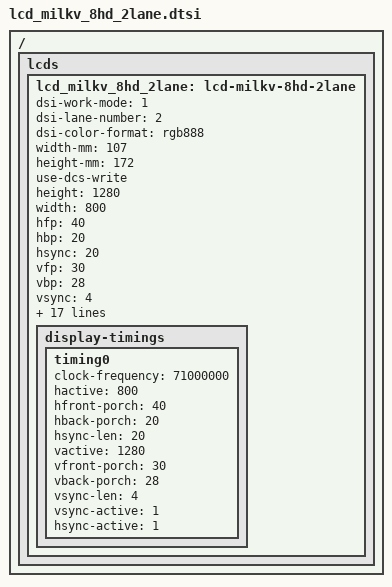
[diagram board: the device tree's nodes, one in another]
// SPDX-License-Identifier: GPL-2.0

/ { lcds: lcds {
	lcd_milkv_8hd_2lane: lcd-milkv-8hd-2lane {
		dsi-work-mode = <1>; /* video burst mode*/
		dsi-lane-number = <2>;
		dsi-color-format = "rgb888";
		width-mm = <107>;
		height-mm = <172>;
		use-dcs-write;

		/*mipi info*/
		height = <1280>;
		width = <800>;
		hfp = <40>;
		hbp = <20>;
		hsync = <20>;
		vfp = <30>;
		vbp = <28>;
		vsync = <4>;
		fps = <60>;
		work-mode = <0>;
		rgb-mode = <3>;
		lane-number = <2>;
		phy-bit-clock = <860000000>;	/* 880 x 1342 * 60 * 24 / 2 = 850,291,200 */
		split-enable = <0>;
		eotp-enable = <0>;
		burst-mode = <2>;
		esd-check-enable = <0>;

		/* DSI_CMD, DSI_MODE, timeout, len, cmd */
		initial-command = [
			39 01 00 02 E0 00
			39 01 00 02 E1 93
			39 01 00 02 E2 65
			39 01 00 02 E3 F8
			39 01 00 02 80 03
			39 01 00 02 E0 01
			39 01 00 02 00 00
			39 01 00 02 01 72
			39 01 00 02 03 00
			39 01 00 02 04 65
			39 01 00 02 0C 74
			39 01 00 02 17 00
			39 01 00 02 18 B7
			39 01 00 02 19 00
			39 01 00 02 1A 00
			39 01 00 02 1B B7
			39 01 00 02 1C 00
			39 01 00 02 24 FE
			39 01 00 02 37 19
			39 01 00 02 38 05
			39 01 00 02 39 00
			39 01 00 02 3A 01
			39 01 00 02 3B 01
			39 01 00 02 3C 70
			39 01 00 02 3D FF
			39 01 00 02 3E FF
			39 01 00 02 3F FF
			39 01 00 02 40 06
			39 01 00 02 41 A0
			39 01 00 02 43 1E
			39 01 00 02 44 0F
			39 01 00 02 45 28
			39 01 00 02 4B 04
			39 01 00 02 55 02
			39 01 00 02 56 01
			39 01 00 02 57 A9
			39 01 00 02 58 0A
			39 01 00 02 59 0A
			39 01 00 02 5A 37
			39 01 00 02 5B 19
			39 01 00 02 5D 78
			39 01 00 02 5E 63
			39 01 00 02 5F 54
			39 01 00 02 60 48
			39 01 00 02 61 45
			39 01 00 02 62 38
			39 01 00 02 63 3D
			39 01 00 02 64 28
			39 01 00 02 65 43
			39 01 00 02 66 41
			39 01 00 02 67 43
			39 01 00 02 68 62
			39 01 00 02 69 50
			39 01 00 02 6A 57
			39 01 00 02 6B 49
			39 01 00 02 6C 44
			39 01 00 02 6D 37
			39 01 00 02 6E 23
			39 01 00 02 6F 10
			39 01 00 02 70 78
			39 01 00 02 71 63
			39 01 00 02 72 54
			39 01 00 02 73 49
			39 01 00 02 74 45
			39 01 00 02 75 38
			39 01 00 02 76 3D
			39 01 00 02 77 28
			39 01 00 02 78 43
			39 01 00 02 79 41
			39 01 00 02 7A 43
			39 01 00 02 7B 62
			39 01 00 02 7C 50
			39 01 00 02 7D 57
			39 01 00 02 7E 49
			39 01 00 02 7F 44
			39 01 00 02 80 37
			39 01 00 02 81 23
			39 01 00 02 82 10
			39 01 00 02 E0 02
			39 01 00 02 00 47
			39 01 00 02 01 47
			39 01 00 02 02 45
			39 01 00 02 03 45
			39 01 00 02 04 4B
			39 01 00 02 05 4B
			39 01 00 02 06 49
			39 01 00 02 07 49
			39 01 00 02 08 41
			39 01 00 02 09 1F
			39 01 00 02 0A 1F
			39 01 00 02 0B 1F
			39 01 00 02 0C 1F
			39 01 00 02 0D 1F
			39 01 00 02 0E 1F
			39 01 00 02 0F 5F
			39 01 00 02 10 5F
			39 01 00 02 11 57
			39 01 00 02 12 77
			39 01 00 02 13 35
			39 01 00 02 14 1F
			39 01 00 02 15 1F
			39 01 00 02 16 46
			39 01 00 02 17 46
			39 01 00 02 18 44
			39 01 00 02 19 44
			39 01 00 02 1A 4A
			39 01 00 02 1B 4A
			39 01 00 02 1C 48
			39 01 00 02 1D 48
			39 01 00 02 1E 40
			39 01 00 02 1F 1F
			39 01 00 02 20 1F
			39 01 00 02 21 1F
			39 01 00 02 22 1F
			39 01 00 02 23 1F
			39 01 00 02 24 1F
			39 01 00 02 25 5F
			39 01 00 02 26 5F
			39 01 00 02 27 57
			39 01 00 02 28 77
			39 01 00 02 29 35
			39 01 00 02 2A 1F
			39 01 00 02 2B 1F
			39 01 00 02 58 40
			39 01 00 02 59 00
			39 01 00 02 5A 00
			39 01 00 02 5B 10
			39 01 00 02 5C 06
			39 01 00 02 5D 40
			39 01 00 02 5E 01
			39 01 00 02 5F 02
			39 01 00 02 60 30
			39 01 00 02 61 01
			39 01 00 02 62 02
			39 01 00 02 63 03
			39 01 00 02 64 6B
			39 01 00 02 65 05
			39 01 00 02 66 0C
			39 01 00 02 67 73
			39 01 00 02 68 09
			39 01 00 02 69 03
			39 01 00 02 6A 56
			39 01 00 02 6B 08
			39 01 00 02 6C 00
			39 01 00 02 6D 04
			39 01 00 02 6E 04
			39 01 00 02 6F 88
			39 01 00 02 70 00
			39 01 00 02 71 00
			39 01 00 02 72 06
			39 01 00 02 73 7B
			39 01 00 02 74 00
			39 01 00 02 75 F8
			39 01 00 02 76 00
			39 01 00 02 77 D5
			39 01 00 02 78 2E
			39 01 00 02 79 12
			39 01 00 02 7A 03
			39 01 00 02 7B 00
			39 01 00 02 7C 00
			39 01 00 02 7D 03
			39 01 00 02 7E 7B
			39 01 00 02 E0 04
			39 01 00 02 00 0E
			39 01 00 02 02 B3
			39 01 00 02 09 60
			39 01 00 02 0E 2A
			39 01 00 02 36 59
			39 01 00 02 E0 00
			39 01 00 02 80 01
			39 01 00 02 E0 00

			39 01 00 01 11
			39 01 78 01 29
		];
		sleep-in-command = [
			39 01 78 01 28
			39 01 78 01 10
		];
		sleep-out-command = [
			39 01 96 01 11
			39 01 32 01 29
		];
		read-id-command = [
			37 01 00 01 05
			14 01 00 05 fb fc fd fe ff
		];

		display-timings {
			timing0 {
				clock-frequency = <71000000>;	/* 880 x 1342 * 60 = 70857600 */
				hactive = <800>;
				hfront-porch = <40>;
				hback-porch = <20>;
				hsync-len = <20>;
				vactive = <1280>;
				vfront-porch = <30>;
				vback-porch = <28>;
				vsync-len = <4>;
				vsync-active = <1>;
				hsync-active = <1>;
			};
		};
	};
};};
